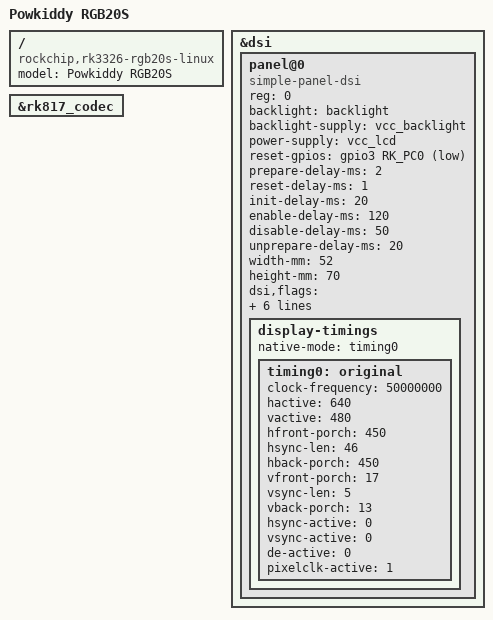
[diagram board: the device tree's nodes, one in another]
// SPDX-License-Identifier: (GPL-2.0+ OR MIT)
/*
* Copyright (c) 2026 kk&lcdyk
*
* Powkiddy RGB20S 
*
*/

/dts-v1/;
#include "rk3326-r36s-panel0-linux.dts"

/ {
	model = "Powkiddy RGB20S ";
	compatible = "rockchip,rk3326-rgb20s-linux", "rockchip,rk3326";
};

&dsi {
	status = "okay";
	
	panel@0 {
		compatible = "simple-panel-dsi";
		reg = <0>;
		/* pwm1 backlight */
		backlight = <&backlight>;
		/* RK817 LDO7 */
		backlight-supply = <&vcc_backlight>;
		/* RK817 LDO8 */
		power-supply = <&vcc_lcd>;
		/* Rev 0.2 LCD reset gpio GPIO3.C0 */
		reset-gpios = <&gpio3 RK_PC0 GPIO_ACTIVE_LOW>;
		prepare-delay-ms = <2>;
		reset-delay-ms = <1>;
		init-delay-ms = <20>;
		enable-delay-ms = <120>;
		disable-delay-ms = <50>;
		unprepare-delay-ms = <20>;
		width-mm = <52>;
		height-mm = <70>;
		dsi,flags  = <(MIPI_DSI_MODE_VIDEO |
		MIPI_DSI_MODE_VIDEO_BURST |
		MIPI_DSI_MODE_LPM |
		MIPI_DSI_MODE_EOT_PACKET)>;
		dsi,format = <MIPI_DSI_FMT_RGB888>;
		dsi,lanes = <4>;
		panel-init-sequence = <0x150002ff 0x30150002 0xff521500 0x2ff0115 0x2e300 0x15000240 0xa150002 0x3401500 0x2040015 0x20503 0x15000224 0x12150002 0x251e1500 0x2262815 0x22752 0x15000228 0x57150002 0x29011500 0x22adf15 0x2389c 0x15000239 0xa7150002 0x3a531500 0x2440015 0x2493c 0x15000259 0xfe150002 0x5c001500 0x2917715 0x29277 0x150002a0 0x55150002 0xa1501500 0x2a49c15 0x2a702 0x150002a8 0x1150002 0xa9011500 0x2aafc15 0x2ab28 0x150002ac 0x6150002 0xad061500 0x2ae0615 0x2af03 0x150002b0 0x8150002 0xb1261500 0x2b22815 0x2b328 0x150002b4 0x33150002 0xb5081500 0x2b62615 0x2b708 0x150002b8 0x26150002 0xff301500 0x2ff5215 0x2ff02 0x150002b0 0xb150002 0xb1161500 0x2b21715 0x2b32c 0x150002b4 0x32150002 0xb53b1500 0x2b62915 0x2b740 0x150002b8 0xd150002 0xb9051500 0x2ba1215 0x2bb10 0x150002bc 0x12150002 0xbd151500 0x2be1915 0x2bf0e 0x150002c0 0x16150002 0xc10a1500 0x2d00c15 0x2d117 0x150002d2 0x14150002 0xd32e1500 0x2d43215 0x2d53c 0x150002d6 0x22150002 0xd73d1500 0x2d80d15 0x2d907 0x150002da 0x13150002 0xdb131500 0x2dc1115 0x2dd15 0x150002de 0x19150002 0xdf101500 0x2e01715 0x2e10a 0x150002ff 0x30150002 0xff521500 0x2ff0315 0x2002a 0x15000201 0x2a150002 0x22a1500 0x2032a15 0x20461 0x15000205 0x80150002 0x6c71500 0x2070115 0x20882 0x15000209 0x83150002 0x302a1500 0x2312a15 0x2322a 0x15000233 0x2a150002 0x34611500 0x235c515 0x23680 0x15000237 0x23150002 0x40821500 0x2418315 0x24280 0x15000243 0x81150002 0x44111500 0x245e615 0x246e5 0x15000247 0x11150002 0x48e81500 0x249e715 0x25002 0x15000251 0x1150002 0x52041500 0x2530315 0x25411 0x15000255 0xea150002 0x56e91500 0x2571115 0x258ec 0x15000259 0xeb150002 0x7e021500 0x27f8015 0x2e05a 0x150002b1 0x150002 0xb40e1500 0x2b50f15 0x2b604 0x150002b7 0x7150002 0xb8061500 0x2b90515 0x2ba0f 0x150002c7 0x150002 0xca0e1500 0x2cb0f15 0x2cc04 0x150002cd 0x7150002 0xce061500 0x2cf0515 0x2d00f 0x15000281 0xf150002 0x840e1500 0x2850f15 0x28607 0x15000287 0x4150002 0x88051500 0x2890615 0x28a00 0x15000297 0xf150002 0x9a0e1500 0x29b0f15 0x29c07 0x1500029d 0x4150002 0x9e051500 0x29f0615 0x2a000 0x150002ff 0x30150002 0xff521500 0x2ff0215 0x20101 0x15000202 0xda150002 0x3ba1500 0x204a815 0x2059a 0x15000206 0x70150002 0x7ff1500 0x2089115 0x20990 0x1500020a 0xff150002 0xb8f1500 0x20c6015 0x20d58 0x1500020e 0x48150002 0xf381500 0x2102b15 0x2ff30 0x150002ff 0x52150002 0xff001500 0x2360215 0x23a70 0x5c80111 0x50a0129>;
		panel-exit-sequence = <0x5140128 0x50a0110>;
		
		display-timings {
			native-mode = <&timing0>;
			
			// 50.00MHz / (640+450+46+450)×(480+17+5+13) = 1586×515 = 61.22 Hz
			timing0: original {
				clock-frequency = <50000000>;
				hactive = <640>;
				vactive = <480>;
				hfront-porch = <450>;
				hsync-len = <46>;
				hback-porch = <450>;
				vfront-porch = <17>;
				vsync-len = <5>;
				vback-porch = <13>;
				hsync-active = <0>;
				vsync-active = <0>;
				de-active = <0>;
				pixelclk-active = <1>;
			};
		};
	};
};

&rk817_codec {
    /delete-property/ spk-mute-delay-ms;
    /delete-property/ use-ext-amplifier;
};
